# EFR32FG23B010F512IM48 register map
Vendor: Silicon Labs; Series: EFR32; File version: C
CPU: CM33 r0p4, little endian, MPU, FPU, DSP, VTOR, 4 interrupt priority bits, 8 SAU regions
Registers are 32-bit, read-write, reset 0x0 unless marked. A register's access mark holds for its fields unless they carry their own. Offsets are from the block's base; [hi:lo] are bit positions.

## DPLL0_NS — DPLL0_NS Registers
Base 0x5001C000
Same registers: DPLL0_S 0x4001C000
0x00 IPVERSION ro reset 0x1
  [31:0] IPVERSION — IP Version ID
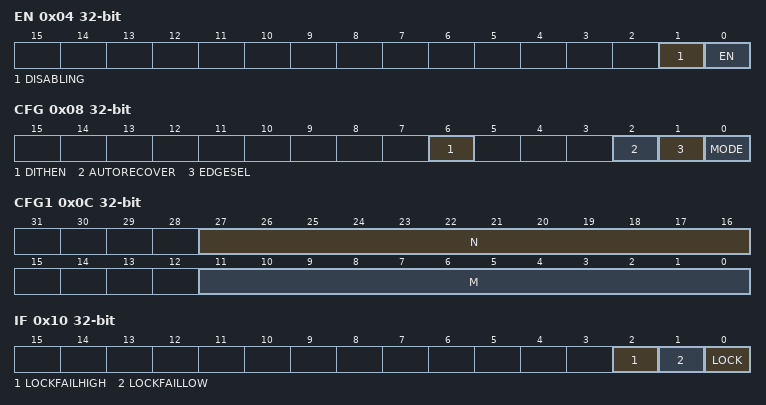
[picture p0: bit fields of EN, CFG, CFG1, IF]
0x04 EN
  [1] DISABLING ro — Disablement Busy Status
  [0] EN — Module Enable
0x08 CFG
  [6] DITHEN — Dither Enable Control
  [2] AUTORECOVER — Automatic Recovery Control
  [1] EDGESEL — Reference Edge Select
  [0] MODE — Operating Mode Control
    0=FLL (Frequency Lock Mode); 1=PLL (Phase Lock Mode)
0x0C CFG1
  [27:16] N — Factor N
  [11:0] M — Factor M
0x10 IF
  [2] LOCKFAILHIGH — Lock Failure High Interrupt Flag
  [1] LOCKFAILLOW — Lock Failure Low Interrupt Flag
  [0] LOCK — Lock Interrupt Flag
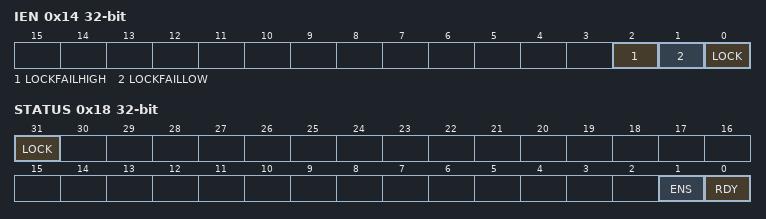
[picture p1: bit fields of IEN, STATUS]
0x14 IEN
  [2] LOCKFAILHIGH — LOCKFAILHIGH Interrupt Enable
  [1] LOCKFAILLOW — LOCKFAILLOW Interrupe Enable
  [0] LOCK — LOCK interrupt Enable
0x18 STATUS ro
  [31] LOCK — Lock Status
    0=UNLOCKED (DPLL is unlocked); 1=LOCKED (DPLL is locked)
  [1] ENS — Enable Status
  [0] RDY — Ready Status
0x24 LOCK wo reset 0x7102
  [15:0] LOCKKEY
    0x7102=UNLOCK (Unlock code)

## FSRCO_NS — FSRCO_NS Registers
Base 0x50018000
Same registers: FSRCO_S 0x40018000
0x00 IPVERSION ro

## GPCRC_NS — GPCRC_NS Registers
Base 0x50088000
Same registers: GPCRC_S 0x40088000
0x00 IPVERSION ro
  [31:0] IPVERSION — IP Version ID
0x04 EN
  [0] EN — CRC Enable
    0=DISABLE (Disable CRC function. Reordering functions are still available. Only BITREVERSE and BYTEREVERSE bits are configurable in this mode.); 1=ENABLE (Writes to INPUTDATA registers will result in CRC operations.)
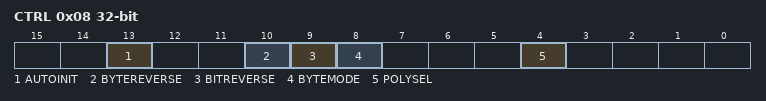
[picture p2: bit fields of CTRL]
0x08 CTRL
  [13] AUTOINIT — Auto Init Enable
  [10] BYTEREVERSE — Byte Reverse Mode
    0=NORMAL (No reverse: B3, B2, B1, B0); 1=REVERSED (Reverse byte order. For 32-bit: B0, B1, B2, B3; For 16-bit: 0, 0, B0, B1)
  [9] BITREVERSE — Byte-level Bit Reverse Enable
    0=NORMAL (No reverse); 1=REVERSED (Reverse bit order in each byte)
  [8] BYTEMODE — Byte Mode Enable
  [4] POLYSEL — Polynomial Select
    0=CRC32 (CRC-32 (0x04C11DB7) polynomial selected); 1=CRC16 (16-bit CRC programmable polynomial selected)
0x0C CMD wo
  [0] INIT — Initialization Enable
0x10 INIT
  [31:0] INIT — CRC Initialization Value
0x14 POLY
  [15:0] POLY — CRC Polynomial Value
0x18 INPUTDATA wo
  [31:0] INPUTDATA — Input Data for 32-bit
0x1C INPUTDATAHWORD wo
  [15:0] INPUTDATAHWORD — Input Data for 16-bit
0x20 INPUTDATABYTE wo
  [7:0] INPUTDATABYTE — Input Data for 8-bit
0x24 DATA ro
  [31:0] DATA — CRC Data Register
0x28 DATAREV ro
  [31:0] DATAREV — Data Reverse Value
0x2C DATABYTEREV ro
  [31:0] DATABYTEREV — Data Byte Reverse Value

## HFRCO0_NS — HFRCO0_NS Registers
Base 0x50010000
Same registers: HFRCO0_S 0x40010000, HFRCOEM23_S 0x4A000000, HFRCOEM23_NS 0x5A000000
0x00 IPVERSION ro reset 0x2
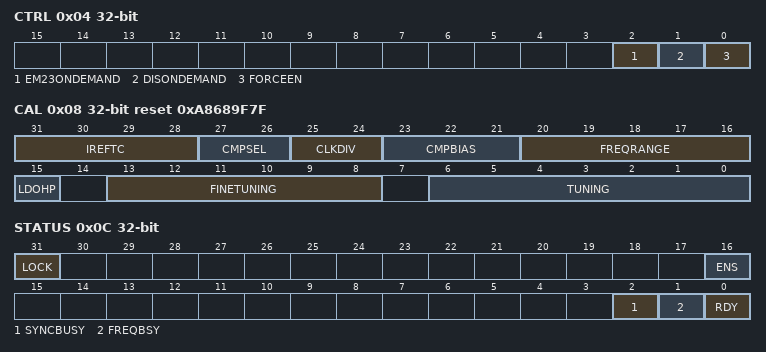
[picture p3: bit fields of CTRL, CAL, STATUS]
0x04 CTRL
  [2] EM23ONDEMAND
  [1] DISONDEMAND — Disable On-demand
  [0] FORCEEN — Force Enable
0x08 CAL reset 0xA8689F7F
  [31:28] IREFTC — Tempco Trim on Comparator Current
  [27:26] CMPSEL — Comparator Load Select
  [25:24] CLKDIV — Locally Divide HFRCO Clock Output
    0=DIV1 (Divide by 1.); 1=DIV2 (Divide by 2.); 2=DIV4 (Divide by 4.)
  [23:21] CMPBIAS — Comparator Bias Current
  [20:16] FREQRANGE — Frequency Range
  [15] LDOHP — LDO High Power Mode
  [13:8] FINETUNING — Fine Tuning Value
  [6:0] TUNING — Tuning Value
0x0C STATUS ro
  [31] LOCK — Lock Status
    0=UNLOCKED (HFRCO is unlocked); 1=LOCKED (HFRCO is locked)
  [16] ENS — Enable Status
  [2] SYNCBUSY — Synchronization Busy
  [1] FREQBSY — Frequency Updating Busy
  [0] RDY — Ready
0x10 IF
  [0] RDY — Ready Interrupt Flag
0x14 IEN
  [0] RDY — RDY Interrupt Enable
0x1C LOCK wo reset 0x8195
  [15:0] LOCKKEY
    0x8195=UNLOCK (Unlock code)
